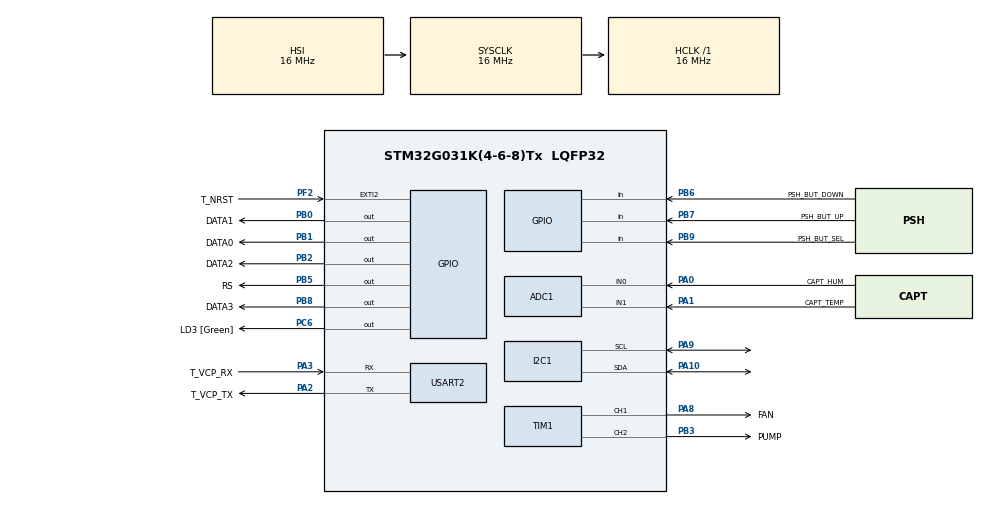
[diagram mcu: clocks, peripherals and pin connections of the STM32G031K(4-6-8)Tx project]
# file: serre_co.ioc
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ADC1.Channel-0\#ChannelRegularConversion=ADC_CHANNEL_0
ADC1.Channel-1\#ChannelRegularConversion=ADC_CHANNEL_1
ADC1.ContinuousConvMode=DISABLE
ADC1.DMAContinuousRequests=ENABLE
ADC1.EOCSelection=ADC_EOC_SEQ_CONV
ADC1.ExternalTrigConv=ADC_EXTERNALTRIG_T2_TRGO
ADC1.LowPowerAutoPowerOff=DISABLE
ADC1.LowPowerAutoWait=DISABLE
ADC1.NbrOfConversion=2
ADC1.NbrOfConversionFlag=1
ADC1.Overrun=ADC_OVR_DATA_PRESERVED
ADC1.Rank-0\#ChannelRegularConversion=1
ADC1.Rank-1\#ChannelRegularConversion=2
ADC1.SamplingTime-0\#ChannelRegularConversion=ADC_SAMPLINGTIME_COMMON_1
ADC1.SamplingTime-1\#ChannelRegularConversion=ADC_SAMPLINGTIME_COMMON_1
ADC1.SamplingTimeCommon1=ADC_SAMPLETIME_39CYCLES_5
ADC1.SamplingTimeCommon2=ADC_SAMPLETIME_39CYCLES_5
ADC1.SelectedChannel=ADC_CHANNEL_0|ADC_CHANNEL_1
ADC1.master=1
Dma.ADC1.0.Direction=DMA_PERIPH_TO_MEMORY
Dma.ADC1.0.EventEnable=DISABLE
Dma.ADC1.0.Instance=DMA1_Channel1
Dma.ADC1.0.MemDataAlignment=DMA_MDATAALIGN_HALFWORD
Dma.ADC1.0.MemInc=DMA_MINC_ENABLE
Dma.ADC1.0.Mode=DMA_CIRCULAR
Dma.ADC1.0.PeriphDataAlignment=DMA_PDATAALIGN_HALFWORD
Dma.ADC1.0.PeriphInc=DMA_PINC_DISABLE
Dma.ADC1.0.Polarity=HAL_DMAMUX_REQ_GEN_RISING
Dma.ADC1.0.Priority=DMA_PRIORITY_LOW
Dma.ADC1.0.RequestNumber=1
Dma.ADC1.0.SignalID=NONE
Dma.ADC1.0.SyncEnable=DISABLE
Dma.ADC1.0.SyncPolarity=HAL_DMAMUX_SYNC_NO_EVENT
Dma.ADC1.0.SyncRequestNumber=1
Dma.ADC1.0.SyncSignalID=NONE
Dma.Request0=ADC1
I2C1.Timing=0x00503D58
Mcu.Family=STM32G0
Mcu.Name=STM32G031K(4-6-8)Tx
Mcu.Package=LQFP32
NVIC.ADC1_IRQn=true\:1\:0\:true\:false\:true\:true\:true\:true
NVIC.DMA1_Channel1_IRQn=true\:0\:0\:false\:false\:true\:false\:true\:true
PA0.GPIO_Label=CAPT_HUM
PA0.Mode=IN0
PA0.Signal=ADC1_IN0
PA1.GPIO_Label=CAPT_TEMP
PA1.Mode=IN1
PA1.Signal=ADC1_IN1
PA10.Mode=I2C
PA10.Signal=I2C1_SDA
PA13.GPIO_Label=T_JTMS
PA13.Mode=Serial_Wire
PA13.Signal=SYS_SWDIO
PA14-BOOT0.GPIO_Label=T_JTCK
PA14-BOOT0.Mode=Serial_Wire
PA14-BOOT0.Signal=SYS_SWCLK
PA2.GPIO_Label=T_VCP_TX
PA2.GPIO_PuPd=GPIO_PULLUP
PA2.Mode=Asynchronous
PA2.Signal=USART2_TX
PA3.GPIO_Label=T_VCP_RX
PA3.GPIO_PuPd=GPIO_PULLUP
PA3.Mode=Asynchronous
PA3.Signal=USART2_RX
PA8.GPIO_Label=FAN
PA8.Signal=S_TIM1_CH1
PA9.Mode=I2C
PA9.Signal=I2C1_SCL
PB0.GPIO_Label=DATA1
PB0.Signal=GPIO_Output
PB1.GPIO_Label=DATA0
PB1.Signal=GPIO_Output
PB2.GPIO_Label=DATA2
PB2.Signal=GPIO_Output
PB3.GPIO_Label=PUMP
PB3.Signal=S_TIM1_CH2
PB5.GPIO_Label=RS
PB5.Signal=GPIO_Output
PB6.GPIO_Label=PSH_BUT_DOWN
PB6.Signal=GPIO_Input
PB7.GPIO_Label=PSH_BUT_UP
PB7.Signal=GPIO_Input
PB8.GPIO_Label=DATA3
PB8.Signal=GPIO_Output
PB9.GPIO_Label=PSH_BUT_SEL
PB9.Signal=GPIO_Input
PC14-OSC32_IN\ (PC14).Mode=LSE-External-Oscillator
PC14-OSC32_IN\ (PC14).Signal=RCC_OSC32_IN
PC15-OSC32_OUT\ (PC15).Mode=LSE-External-Oscillator
PC15-OSC32_OUT\ (PC15).Signal=RCC_OSC32_OUT
PC6.GPIO_Label=LD3 [Green]
PC6.Signal=GPIO_Output
PF2\ -\ NRST.GPIO_Label=T_NRST
PF2\ -\ NRST.Signal=GPXTI2
ProjectManager.HeapSize=0x200
ProjectManager.StackSize=0x400
ProjectManager.TargetToolchain=STM32CubeIDE
RCC.AHBFreq_Value=16000000
RCC.CortexFreq_Value=16000000
RCC.EXTERNAL_CLOCK_VALUE=12288000
RCC.HCLKFreq_Value=16000000
RCC.HSE_VALUE=8000000
RCC.HSI_VALUE=16000000
RCC.PLLQ=RCC_PLLQ_DIV4
RCC.SYSCLKFreq_VALUE=16000000
RCC.VCOOutputFreq_Value=128000000
SH.S_TIM1_CH1.0=TIM1_CH1,PWM Generation1 CH1
SH.S_TIM1_CH2.0=TIM1_CH2,PWM Generation2 CH2
TIM1.Channel-PWM\ Generation1\ CH1=TIM_CHANNEL_1
TIM1.Channel-PWM\ Generation2\ CH2=TIM_CHANNEL_2
TIM2.AutoReloadPreload=TIM_AUTORELOAD_PRELOAD_ENABLE
TIM2.Period=19999
TIM2.Prescaler=1599
TIM2.TIM_MasterOutputTrigger=TIM_TRGO_UPDATE
TIM2.TIM_MasterSlaveMode=TIM_MASTERSLAVEMODE_DISABLE
USART2.VirtualMode-Asynchronous=VM_ASYNC
USART2.WordLength=WORDLENGTH_7B
VP_TIM1_VS_ClockSourceINT.Mode=Internal
VP_TIM2_VS_ClockSourceINT.Mode=Internal
board=NUCLEO-G031K8

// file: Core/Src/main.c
/* USER CODE BEGIN Header */
/**
  ******************************************************************************
  * @file           : main.c
  * @brief          : Main program body
  ******************************************************************************
  * @attention
  *
  * Copyright (c) 2025 STMicroelectronics.
  * All rights reserved.
  *
  * This software is licensed under terms that can be found in the LICENSE file
  * in the root directory of this software component.
  * If no LICENSE file comes with this software, it is provided AS-IS.
  *
  ******************************************************************************
  */
/* USER CODE END Header */
#include "main.h"
#include "adc.h"
#include "dma.h"
#include "i2c.h"
#include "tim.h"
#include "usart.h"
#include "gpio.h"

void SystemClock_Config(void);

int main(void)
{

  /* MCU Configuration--------------------------------------------------------*/

  /* Reset of all peripherals, Initializes the Flash interface and the Systick. */
  HAL_Init();

  /* Configure the system clock */
  SystemClock_Config();

  /* Initialize all configured peripherals */
  MX_GPIO_Init();
  MX_DMA_Init();
  MX_USART2_UART_Init();
  MX_ADC1_Init();
  MX_I2C1_Init();
  MX_TIM1_Init();
  MX_TIM2_Init();
  /* USER CODE BEGIN 2 */
  main_serre_init();
  /* USER CODE END 2 */

  /* Infinite loop */
  /* USER CODE BEGIN WHILE */
  while (1)
  {
    main_serre();
    /* USER CODE END WHILE */

  }
}

void SystemClock_Config(void)
{
  RCC_OscInitTypeDef RCC_OscInitStruct = {0};
  RCC_ClkInitTypeDef RCC_ClkInitStruct = {0};

  /** Configure the main internal regulator output voltage
  */
  HAL_PWREx_ControlVoltageScaling(PWR_REGULATOR_VOLTAGE_SCALE1);

  /** Initializes the RCC Oscillators according to the specified parameters
  * in the RCC_OscInitTypeDef structure.
  */
  RCC_OscInitStruct.OscillatorType = RCC_OSCILLATORTYPE_HSI;
  RCC_OscInitStruct.HSIState = RCC_HSI_ON;
  RCC_OscInitStruct.HSIDiv = RCC_HSI_DIV1;
  RCC_OscInitStruct.HSICalibrationValue = RCC_HSICALIBRATION_DEFAULT;
  RCC_OscInitStruct.PLL.PLLState = RCC_PLL_NONE;
  if (HAL_RCC_OscConfig(&RCC_OscInitStruct) != HAL_OK)
  {
    Error_Handler();
  }

  /** Initializes the CPU, AHB and APB buses clocks
  */
  RCC_ClkInitStruct.ClockType = RCC_CLOCKTYPE_HCLK|RCC_CLOCKTYPE_SYSCLK
                              |RCC_CLOCKTYPE_PCLK1;
  RCC_ClkInitStruct.SYSCLKSource = RCC_SYSCLKSOURCE_HSI;
  RCC_ClkInitStruct.AHBCLKDivider = RCC_SYSCLK_DIV1;
  RCC_ClkInitStruct.APB1CLKDivider = RCC_HCLK_DIV1;

  if (HAL_RCC_ClockConfig(&RCC_ClkInitStruct, FLASH_LATENCY_0) != HAL_OK)
  {
    Error_Handler();
  }
}

void Error_Handler(void)
{
  __disable_irq();
  while (1)
  {
  }
}
